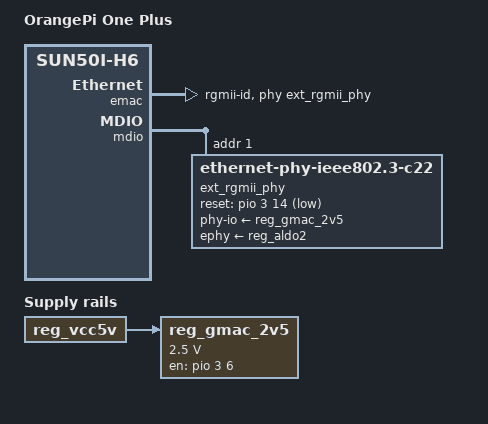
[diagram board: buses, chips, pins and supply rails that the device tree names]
// SPDX-License-Identifier: (GPL-2.0+ OR MIT)
// Copyright (C) 2018 Amarula Solutions
// Author: Jagan Teki <jagan@amarulasolutions.com>

#include "sun50i-h6-orangepi.dtsi"

/ {
	model = "OrangePi One Plus";
	compatible = "xunlong,orangepi-one-plus", "allwinner,sun50i-h6";

	aliases {
		ethernet0 = &emac;
	};

	reg_gmac_2v5: gmac-2v5 {
		compatible = "regulator-fixed";
		regulator-name = "gmac-2v5";
		regulator-min-microvolt = <2500000>;
		regulator-max-microvolt = <2500000>;
		enable-active-high;
		gpio = <&pio 3 6 GPIO_ACTIVE_HIGH>; /* PD6 */
		off-on-delay-us = <100000>;
		vin-supply = <&reg_vcc5v>;
	};
};

&emac {
	pinctrl-names = "default";
	pinctrl-0 = <&ext_rgmii_pins>;
	phy-mode = "rgmii-id";
	phy-handle = <&ext_rgmii_phy>;
	allwinner,rx-delay-ps = <200>;
	allwinner,tx-delay-ps = <200>;
	status = "okay";
};

&mdio {
	ext_rgmii_phy: ethernet-phy@1 {
		compatible = "ethernet-phy-ieee802.3-c22";
		reg = <1>;
		/*
		 * The board uses 2.5V RGMII signalling. Power sequence to enable
		 * the phy is to enable GMAC-2V5 and GMAC-3V (aldo2) power rails
		 * at the same time and to wait 100ms. The driver enables phy-io
		 * first. Delay is achieved with enable-ramp-delay on reg_aldo2.
		 */
		phy-io-supply = <&reg_gmac_2v5>;
		ephy-supply = <&reg_aldo2>;

		reset-gpios = <&pio 3 14 GPIO_ACTIVE_LOW>; /* PD14 */
		reset-assert-us = <15000>;
		reset-deassert-us = <40000>;
	};
};

&reg_aldo2 {
	regulator-enable-ramp-delay = <100000>;
};
